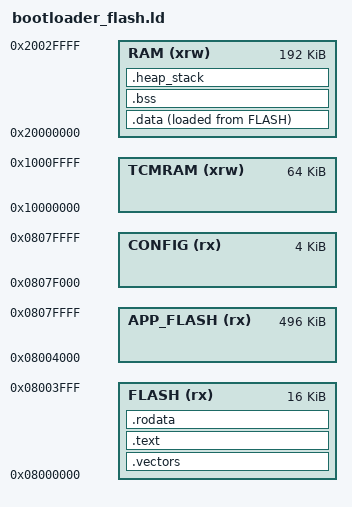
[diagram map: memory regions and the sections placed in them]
/* Bootloader链接脚本 */
MEMORY
{
  /* Bootloader占用前16KB */
  FLASH (rx)      : ORIGIN = 0x08000000, LENGTH = 16K
  /* 应用程序从16KB开始 */
  APP_FLASH (rx)  : ORIGIN = 0x08004000, LENGTH = 496K
  /* 配置区域最后4KB */
  CONFIG (rx)     : ORIGIN = 0x0807F000, LENGTH = 4K
  RAM (xrw)       : ORIGIN = 0x20000000, LENGTH = 192K
  TCMRAM (xrw)    : ORIGIN = 0x10000000, LENGTH = 64K
}

ENTRY(Reset_Handler)

SECTIONS
{
  __stack_size = DEFINED(__stack_size) ? __stack_size : 2K;
  __heap_size = DEFINED(__heap_size) ? __heap_size : 1K;

  /* Bootloader向量表 */
  .vectors :
  {
    . = ALIGN(4);
    KEEP(*(.vectors))
    . = ALIGN(4);
    __Vectors_End = .;
    __Vectors_Size = __Vectors_End - __gVectors;
  } >FLASH

  /* Bootloader代码段 */
  .text :
  {
    . = ALIGN(4);
    *(.text)
    *(.text*)
    *(.glue_7)
    *(.glue_7t)
    *(.eh_frame)
    KEEP (*(.init))
    KEEP (*(.fini))
    . = ALIGN(4);
    _etext = .;
  } >FLASH

  /* 只读数据 */
  .rodata :
  {
    . = ALIGN(4);
    *(.rodata)
    *(.rodata*)
    . = ALIGN(4);
  } >FLASH

  /* 应用程序起始地址定义 */
  __app_start = ORIGIN(APP_FLASH);
  __config_start = ORIGIN(CONFIG);

  /* 数据段 */
  _sidata = LOADADDR(.data);
  .data :
  {
    . = ALIGN(4);
    _sdata = .;
    *(.data)
    *(.data*)
    . = ALIGN(4);
    _edata = .;
  } > RAM AT> FLASH

  /* BSS段 */
  . = ALIGN(4);
  .bss :
  {
    . = ALIGN(4);
    _sbss = .;
    __bss_start__ = _sbss;
    *(.bss)
    *(.bss*)
    *(COMMON)
    . = ALIGN(4);
    _ebss = .;
    __bss_end__ = _ebss;
  } > RAM

  /* 堆栈空间 */
  .heap_stack :
  {
    . = ALIGN(8);
    PROVIDE ( end = _ebss );
    PROVIDE ( _end = _ebss );
    . = . + __heap_size;
    PROVIDE( _heap_end = . );
    . = . + __stack_size;
    PROVIDE( _sp = . ); 
    . = ALIGN(8);
  } > RAM
}
